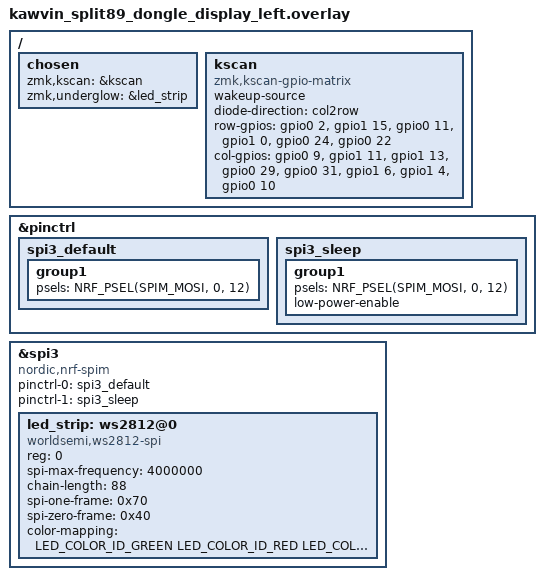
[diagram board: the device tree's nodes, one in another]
/*
 * Copyright (c) 2023 The ZMK Contributors
 *
 * SPDX-License-Identifier: MIT
 */

#include "kawvin_split89_dongle_display.dtsi"
#include <dt-bindings/led/led.h>
&pinctrl {
    // Other pinctrl definitions for other hardware
    
/*
    i2c1_default: i2c1_default {
        group1 {
            psels = <NRF_PSEL(TWIM_SDA, 0, 17)>,
                    <NRF_PSEL(TWIM_SCL, 0, 20)>;
        };
    };

    i2c1_sleep: i2c1_sleep {
        group1 {
            psels = <NRF_PSEL(TWIM_SDA, 0, 17)>,
                    <NRF_PSEL(TWIM_SCL, 0, 20)>;
            low-power-enable;
        };
    };
*/

    spi3_default: spi3_default {
        group1 {
            psels = <NRF_PSEL(SPIM_MOSI, 0, 12)>;
        };
    };

    spi3_sleep: spi3_sleep {
        group1 {
            psels = <NRF_PSEL(SPIM_MOSI, 0, 12)>;
            low-power-enable;
        };
    };
};


&spi3 {
    compatible = "nordic,nrf-spim";
    status = "okay";

    pinctrl-0 = <&spi3_default>;
    pinctrl-1 = <&spi3_sleep>;
    pinctrl-names = "default", "sleep";

    led_strip: ws2812@0 {
        compatible = "worldsemi,ws2812-spi";

        /* SPI */
        reg = <0>; /* ignored, but necessary for SPI bindings */
        spi-max-frequency = <4000000>;

        /* WS2812 */
        chain-length = <88>; /* arbitrary; change at will */
        spi-one-frame = <0x70>;
        spi-zero-frame = <0x40>;
        color-mapping = <LED_COLOR_ID_GREEN LED_COLOR_ID_RED LED_COLOR_ID_BLUE>;
    };
};
/*
&i2c1 {
	status = "okay";
	//compatible = "nordic,nrf-twi";
	pinctrl-0 = <&i2c1_default>;
	pinctrl-1 = <&i2c1_sleep>;
	pinctrl-names = "default", "sleep";
    
	oled1: ssd1306@3c {
		compatible = "solomon,ssd1306fb";
		reg = <0x3c>;
		label = "DISPLAY";
		width = <128>;
		height = <32>;
		segment-offset = <0>;
		page-offset = <0>;
		display-offset = <0>;
		multiplex-ratio = <31>;
		segment-remap;
		com-invdir;
		inversion-on;   // 翻转颜色
		//com-sequential;
		prechargep = <0x22>;
	};
};
*/
/ {
    chosen {
        zmk,kscan = &kscan;
        //zephyr,display = &oled1;
        zmk,underglow = &led_strip;
    };

    kscan: kscan {
        compatible = "zmk,kscan-gpio-matrix";
        wakeup-source;

        diode-direction = "col2row";

        row-gpios
            = <&gpio0  2 (GPIO_PULL_DOWN | GPIO_ACTIVE_HIGH)>
            , <&gpio1 15 (GPIO_PULL_DOWN | GPIO_ACTIVE_HIGH)>
            , <&gpio0 11 (GPIO_PULL_DOWN | GPIO_ACTIVE_HIGH)>
            , <&gpio1  0 (GPIO_PULL_DOWN | GPIO_ACTIVE_HIGH)>
            , <&gpio0 24 (GPIO_PULL_DOWN | GPIO_ACTIVE_HIGH)>
            , <&gpio0 22 (GPIO_PULL_DOWN | GPIO_ACTIVE_HIGH)>
            ;

        col-gpios
            = <&gpio0  9 GPIO_ACTIVE_HIGH>
            , <&gpio1 11 GPIO_ACTIVE_HIGH>
            , <&gpio1 13 GPIO_ACTIVE_HIGH>
            , <&gpio0 29 GPIO_ACTIVE_HIGH>
            , <&gpio0 31 GPIO_ACTIVE_HIGH>
            , <&gpio1  6 GPIO_ACTIVE_HIGH>
            , <&gpio1  4 GPIO_ACTIVE_HIGH>
            , <&gpio0 10 GPIO_ACTIVE_HIGH>
            ;
    };

};


